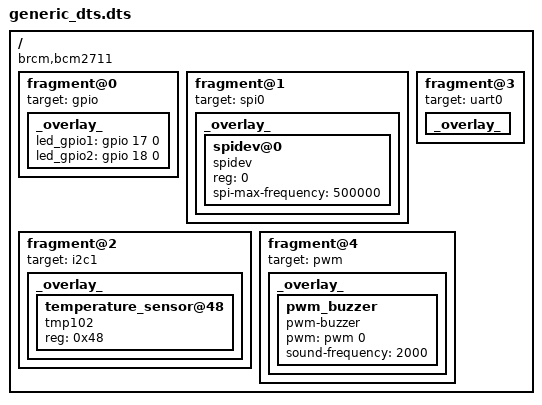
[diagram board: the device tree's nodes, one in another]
/dts-v1/;
/plugin/;

/ {
    compatible = "brcm,bcm2711";  // Raspberry Pi 4 Model B

    // Define GPIO LED
    fragment@0 {
        target = <&gpio>;
        _overlay_ {
            led_gpio1 = <&gpio 17 0>;  // GPIO 17 for LED1
            led_gpio2 = <&gpio 18 0>;  // GPIO 18 for LED2
        };
    };

    // Define SPI Device
    fragment@1 {
        target = <&spi0>;  // SPI0 peripheral
        _overlay_ {
            status = "okay";  // Enable SPI0

            spidev@0 {
                compatible = "spidev";
                reg = <0>;  // Chip select 0
                spi-max-frequency = <500000>;  // Max 500kHz
            };
        };
    };

    // Define I2C Device
    fragment@2 {
        target = <&i2c1>;  // I2C1 peripheral
        _overlay_ {
            status = "okay";  // Enable I2C1

            temperature_sensor@48 {
                compatible = "tmp102";  // Example I2C device (TMP102)
                reg = <0x48>;  // Device I2C address
            };
        };
    };

    // Define UART Device
    fragment@3 {
        target = <&uart0>;  // UART0 peripheral
        _overlay_ {
            status = "okay";  // Enable UART0
        };
    };

    // Define PWM for Buzzer
    fragment@4 {
        target = <&pwm>;
        _overlay_ {
            pwm_buzzer {
                compatible = "pwm-buzzer";
                pwm = <&pwm 0>;  // Use PWM channel 0
                sound-frequency = <2000>;  // Default frequency 2kHz
            };
        };
    };
};
